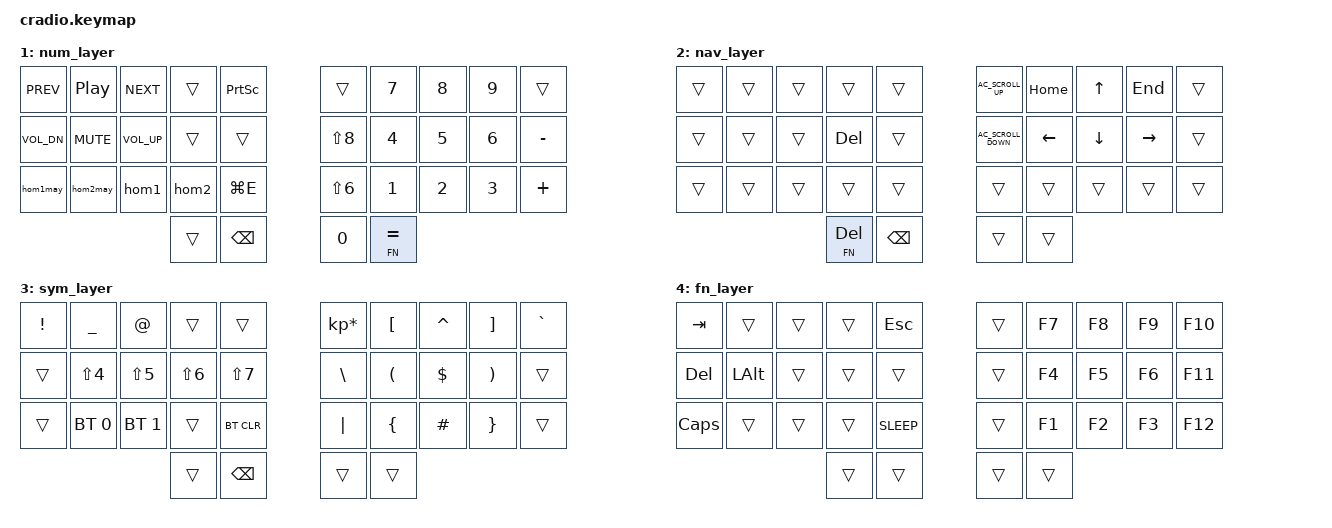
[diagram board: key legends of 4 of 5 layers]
/*
 * Copyright (c) 2020 The ZMK Contributors
 *
 * SPDX-License-Identifier: MIT
 */

#include <behaviors.dtsi>
#include <dt-bindings/zmk/keys.h>
#include <dt-bindings/zmk/bt.h>
#include <dt-bindings/zmk/outputs.h>
#include <dt-bindings/zmk/behaviors.h>
//  #include <dt-bindings/zmk/dynamic-macros.h>
 
 // Home row mods macro
#define HRML(k1,k2,k3) &ht LALT k1  &ht LSHIFT k2 &ht LCTRL k3 
#define HRMR(k1,k2,k3,k4) &ht RCTRL k1  &ht RSHIFT k2  &ht LALT k3 &ht RGUI k4

 // Layer tap macro 
// define layers
#define COLEMAK 0
#define NUM 1
#define NAV 2
#define SYM 3
#define FN 4

 
 
/ { 
      
    behaviors {
        ht: hold_tap {
            label = "hold_tap";
            compatible = "zmk,behavior-hold-tap";
            #binding-cells = <2>;
            flavor = "tap-preferred";
            tapping-term-ms = <150>;
            quick-tap-ms = <100>;
            global-quick-tap;
            bindings = <&kp>, <&kp>;
        };

        td0: tap_dance_0 {
            compatible = "zmk,behavior-tap-dance";
            #binding-cells = <0>;
            tapping-term-ms = <300>;
            bindings = <&kp COMMA>, <&kp SEMICOLON>;
        };

        td1: tap_dance_1 {
            compatible = "zmk,behavior-tap-dance";
            #binding-cells = <0>;
            tapping-term-ms = <300>;
            bindings = <&kp Q>, <&kp TAB>;
        };

        td2: tap_dance_2 {
            compatible = "zmk,behavior-tap-dance";
            #binding-cells = <0>;
            tapping-term-ms = <300>;
            bindings = <&kp SLASH>, <&kp ESC>;
        };

        // homologo: homologo {
        //     compatible = "zmk,behavior-send-string";
        //     #binding-cells = <0>;
        //     text = "`respaldo-inteligencia-riesgo.cobranza.HOMOLOGA_CUENTAS`()";
        // };

    };

    combos {
        compatible = "zmk,combos";
            combo_fp_caps {
            timeout-ms = <50>;
            key-positions = <8 9>;
            bindings = <&kp CAPS>;
        };
    };
    

    // macros {
    //     dyn-macro: dyn-macro {
    //         label = "ZM_dynamic-macro";
    //         compatible = "zmk,behavior-dynamic-macro";
    //         #binding-cells = <1>;
    //     };
    // };

    macros {
        hom1: hom1 {
            label = "HOMOLOGO1";
            compatible = "zmk,behavior-macro";
            #binding-cells = <0>;
            wait-ms = <30>;
            tap-ms = <30>;
            bindings
                = <&macro_tap &kp GRAVE>
                , <&macro_tap &kp R &kp E &kp S &kp P &kp A &kp L &kp D &kp O>
                , <&macro_tap &kp MINUS>
                , <&macro_tap &kp I &kp N &kp T &kp E &kp L &kp I &kp G &kp E &kp N &kp C &kp I &kp A>
                , <&macro_tap &kp MINUS>
                , <&macro_tap &kp R &kp I &kp E &kp S &kp G &kp O>
                ;
        };

        hom2: hom2 {
            label = "HOMOLOGO2";
            compatible = "zmk,behavior-macro";
            #binding-cells = <0>;
            wait-ms = <30>;
            tap-ms = <30>;
            bindings
                = <&macro_tap &kp DOT>
                , <&macro_tap &kp C &kp O &kp B &kp R &kp A &kp N &kp Z &kp A>
                , <&macro_tap &kp DOT>
                , <&macro_press &kp LSHFT>
                , <&macro_tap &kp H &kp O &kp M &kp O &kp L &kp O &kp G &kp A>
                , <&macro_release &kp LSHFT>
                , <&macro_tap &kp UNDER>
                , <&macro_press &kp LSHFT>
                , <&macro_tap &kp C &kp U &kp E &kp N &kp T &kp A &kp S>
                , <&macro_release &kp LSHFT>
                , <&macro_tap &kp GRAVE>
                , <&macro_tap &kp LPAR &kp RPAR>
                ;
        };

        hom1may: hom1may {
            label = "HOMOLOGO1MAYUS";
            compatible = "zmk,behavior-macro";
            #binding-cells = <0>;
            wait-ms = <30>;
            tap-ms = <30>;
            bindings
                = <&macro_tap &kp GRAVE>
                // Presionamos Shift para que el PC convierta estas letras en minúsculas
                , <&macro_press &kp LSHFT>
                , <&macro_tap &kp R &kp E &kp S &kp P &kp A &kp L &kp D &kp O>
                , <&macro_release &kp LSHFT>
                , <&macro_tap &kp MINUS>
                , <&macro_press &kp LSHFT>
                , <&macro_tap &kp I &kp N &kp T &kp E &kp L &kp I &kp G &kp E &kp N &kp C &kp I &kp A>
                , <&macro_release &kp LSHFT>
                , <&macro_tap &kp MINUS>
                , <&macro_press &kp LSHFT>
                , <&macro_tap &kp R &kp I &kp E &kp S &kp G &kp O>
                , <&macro_release &kp LSHFT>
                ;
        };

        hom2may: hom2may {
            label = "HOMOLOGO2MAYUS";
            compatible = "zmk,behavior-macro";
            #binding-cells = <0>;
            wait-ms = <30>;
            tap-ms = <30>;
            bindings
                = <&macro_tap &kp DOT>
                , <&macro_press &kp LSHFT>
                , <&macro_tap &kp C &kp O &kp B &kp R &kp A &kp N &kp Z &kp A>
                , <&macro_release &kp LSHFT>
                , <&macro_tap &kp DOT>
                , <&macro_tap &kp H &kp O &kp M &kp O &kp L &kp O &kp G &kp A>
                , <&macro_tap &kp UNDER>
                , <&macro_tap &kp C &kp U &kp E &kp N &kp T &kp A &kp S>
                , <&macro_tap &kp GRAVE>
                , <&macro_tap &kp LPAR &kp RPAR>
                ;
        };
    };
        //  strings {
            //      HOMOLOGO = "`respaldo-inteligencia-riesgo.cobranza.HOMOLOGA_CUENTAS`()";
            //      CREATE_TB = "CREATE OR REPLACE TABLE `respaldo-inteligencia-riesgo.WSP_GJORQUERA.CREATE_TB`";
            //  };
            
            
        keymap { //FALTA DOBLE TAP DANCE PARA ;
            compatible = "zmk,keymap";
            default_layer {
                bindings = <
        //╭──────────┬──────────┬──────────┬──────────┬──────────╮   ╭──────────┬──────────┬──────────┬──────────┬──────────╮
        //│  Q       │  W       │  E       │  R       │  T       │   │  Y       │  U       │  I       │  O       │  P       │
            &td1      &kp W      &kp F      &kp P      &kp G          &kp J      &kp L      &kp U      &kp Y      &kp SQT
        //├──────────┼──────────┼──────────┼──────────┼──────────┤   ├──────────┼──────────┼──────────┼──────────┼──────────┤
        //│  A       │  S       │  D       │  F       │  G       │   │  H       │  J       │  K       │  L       │BACKSPACE │
            &kp A     HRML(R,         S,         T)     &kp D          &kp H      HRMR(N,        E,           I,       O)
        //├──────────┼──────────┼──────────┼──────────┼──────────┤   ├──────────┼──────────┼──────────┼──────────┼──────────┤
        //│  Z       │  X       │  C       │  V       │  B       │   │  N       │  M       │ , <      │ . >      │ ENTER    │
            &ht LGUI Z  &kp X      &kp C      &kp V      &kp B          &kp K     &kp M      &td0      &kp DOT    &td2
        //╰──────────┴──────────┴──────────┼──────────┼──────────┤   ├──────────┼──────────┼──────────┴──────────┴──────────╯
                                           &lt NUM LGUI  &ht RALT BSPC    &lt SYM ENTER  &lt NAV SPACE
        //                                 ╰──────────┴──────────╯   ╰──────────┴──────────╯
            >;
        };

        num_layer { //FALTA MACRO DE HOMOLOGO
            bindings = <
        //╭─────────────┬──────────┬──────────┬──────────┬──────────╮   ╭──────────┬──────────┬──────────┬──────────┬──────────╮
        //│  Q          │  W       │  E       │  R       │  T       │   │  Y       │  U       │  I       │  O       │  P       │
            &kp C_PREV   &kp C_PP   &kp C_NEXT &trans     &kp PSCRN      &trans      &kp N7     &kp N8     &kp N9     &trans
        //├─────────────┼──────────┼──────────┼──────────┼──────────┤   ├──────────┼──────────┼──────────┼──────────┼──────────┤
        //│  A          │  S       │  D       │  F       │  G       │   │  H       │  J       │  K       │  L       │BACKSPACE │
            &kp C_VOL_DN &kp C_MUTE &kp C_VOL_UP &trans   &trans         &kp LS(N8) &kp N4     &kp N5     &kp N6     &kp MINUS   
        //├─────────────┼──────────┼──────────┼──────────┼──────────┤   ├──────────┼──────────┼──────────┼──────────┼──────────┤
        //│  Z          │  X       │  C       │  V       │  B       │   │  N       │  M       │ , <      │ . >      │ ENTER    │
            &hom1may      &hom2may  &hom1       &hom2       &kp LG(E)     &kp LS(N6) &kp N1      &kp N2    &kp N3      &kp PLUS
        //╰─────────────┴──────────┴──────────┼──────────┼──────────┤   ├──────────┼──────────┼──────────┴──────────┴──────────╯
                                               &trans     &kp BSPC       &kp N0     &lt FN EQUAL
        //                                    ╰──────────┴──────────╯   ╰──────────┴──────────╯
            >;
        };

        nav_layer {
            bindings = <
        //╭──────────┬──────────┬──────────┬──────────┬──────────╮    ╭────────────────────┬──────────┬──────────┬──────────┬──────────╮
        //│  Q       │  W       │  E       │  R       │  T       │    │  Y                 │  U       │  I       │  O       │  P       │
            &trans      &trans      &trans      &trans      &trans     &kp C_AC_SCROLL_UP    &kp HOME   &kp UP     &kp END    &trans
        //├──────────┼──────────┼──────────┼──────────┼──────────┤    ├────────────────────┼──────────┼──────────┼──────────┼──────────┤
        //│  A       │  S       │  D       │  F       │  G       │    │  H                 │  J       │  K       │  L       │BACKSPACE │
            &trans    &trans        &trans    &kp DEL      &trans      &kp C_AC_SCROLL_DOWN  &kp LEFT   &kp DOWN   &kp RIGHT  &trans   
        //├──────────┼──────────┼──────────┼──────────┼──────────┤    ├────────────────────┼──────────┼──────────┼──────────┼──────────┤
        //│  Z       │  X       │  C       │  V       │  B       │    │  N                 │  M       │ , <      │ . >      │ ENTER    │
            &trans      &trans      &trans     &trans      &trans      &trans                &trans     &trans     &trans     &trans
        //╰──────────┴──────────┴──────────┼──────────┼──────────┤    ├────────────────────┼──────────┼──────────┴──────────┴──────────╯
                                           &lt FN DEL     &kp BSPC     &trans                &trans
        //                                 ╰──────────┴──────────╯    ╰────────────────────┴──────────╯
            >;
        };

        sym_layer {
            bindings = <
        //╭────────────┬──────────┬──────────┬──────────┬──────────╮   ╭────────────────┬──────────┬──────────┬──────────┬──────────╮
        //│  Q         │  W       │  E       │  R       │  T       │   │  Y             │  U       │  I       │  O       │  P       │
            &kp EXCL    &kp UNDER  &kp AT     &trans     &trans         &kp KP_ASTERISK  &kp LBKT   &kp CARET  &kp RBKT   &kp GRAVE
        //├────────────┼──────────┼──────────┼──────────┼──────────┤   ├────────────────┼──────────┼──────────┼──────────┼──────────┤
        //│  A         │  S       │  D       │  F       │  G       │   │  H             │  J       │  K       │  L       │BACKSPACE │
            &trans      &kp LS(N4) &kp LS(N5) &kp LS(N6) &kp LS(N7)     &kp BSLH         &kp LPAR   &kp DLLR   &kp RPAR   &trans   
        //├────────────┼──────────┼──────────┼──────────┼──────────┤   ├────────────────┼──────────┼──────────┼──────────┼──────────┤
        //│  Z         │  X       │  C       │  V       │  B       │   │  N             │  M       │ , <      │ . >      │ ENTER    │
            &trans  &bt BT_SEL 0 &bt BT_SEL 1  &trans  &bt BT_CLR       &kp PIPE          &kp LBRC  &kp HASH   &kp RBRC   &trans
        //╰────────────┴──────────┴──────────┼──────────┼──────────┤   ├────────────────┼──────────┼──────────┴──────────┴──────────╯
                                              &trans     &kp BSPC        &trans    &trans
        //                                   ╰──────────┴──────────╯   ╰──────────┴──────────╯
            >;
        };

        fn_layer {
            bindings = <
        //╭──────────┬──────────┬──────────┬──────────┬──────────╮   ╭──────────┬──────────┬──────────┬──────────┬──────────╮
        //│  Q       │  W       │  E       │  R       │  T       │   │  Y       │  U       │  I       │  O       │  P       │
            &kp TAB    &trans      &trans     &trans   &kp ESC        &trans     &kp F7     &kp F8     &kp F9     &kp F10
        //├──────────┼──────────┼──────────┼──────────┼──────────┤   ├──────────┼──────────┼──────────┼──────────┼──────────┤
        //│  A       │  S       │  D       │  F       │  G       │   │  H       │  J       │  K       │  L       │BACKSPACE │
            &kp DEL    &kp LALT    &trans     &trans   &trans         &trans     &kp F4     &kp F5     &kp F6     &kp F11   
        //├──────────┼──────────┼──────────┼──────────┼──────────┤   ├──────────┼──────────┼──────────┼──────────┼──────────┤
        //│  Z       │  X       │  C       │  V       │  B       │   │  N       │  M       │ , <      │ . >      │ ENTER    │
            &kp CAPS   &trans      &trans     &trans   &kp C_SLEEP    &trans     &kp F1     &kp F2     &kp F3     &kp F12
        //╰──────────┴──────────┴──────────┼──────────┼──────────┤   ├──────────┼──────────┼──────────┴──────────┴──────────╯
                                            &trans      &trans         &trans  &trans
        //                                 ╰──────────┴──────────╯   ╰──────────┴──────────╯
            >;
        };
    };
 };
 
